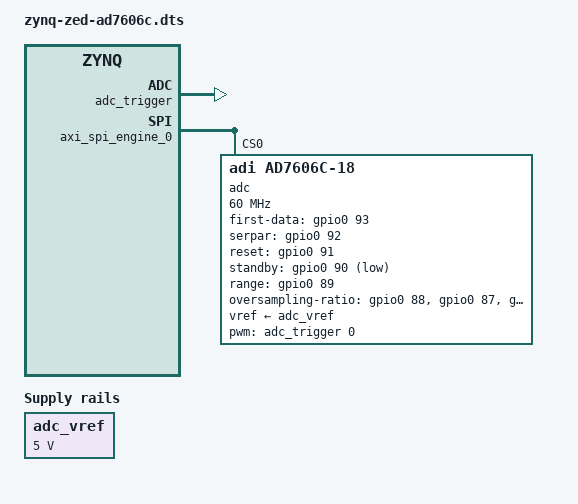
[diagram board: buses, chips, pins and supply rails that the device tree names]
// SPDX-License-Identifier: GPL-2.0
/*
 * Analog Devices AD7606C
 * https://www.analog.com/en/products/ad7606c-18.html
 * https://wiki.analog.com/resources/tools-software/linux-drivers/platforms/zynq
 *
 * hdl_project: <ad760x_fmc/zed>
 * board_revision: <>
 *
 * Copyright (C) 2012-2019 Analog Devices Inc.
 */
/dts-v1/;

#include <dt-bindings/gpio/gpio.h>
#include <dt-bindings/interrupt-controller/irq.h>
#include "zynq-zed.dtsi"
#include "zynq-zed-adv7511.dtsi"

/ {
	adc_vref: regulator-vref {
		compatible = "regulator-fixed";
		regulator-name = "fixed-supply";
		regulator-min-microvolt = <5000000>;
		regulator-max-microvolt = <5000000>;
		regulator-always-on;
	};
};

&fpga_axi {
	rx_dma: rx-dmac@44a30000 {
		compatible = "adi,axi-dmac-1.00.a";
		reg = <0x44a30000 0x1000>;
		#dma-cells = <1>;
		interrupt-parent = <&intc>;
		interrupts = <0 57 IRQ_TYPE_LEVEL_HIGH>;
		clocks = <&clkc 16>;

		adi,channels {
			#size-cells = <0>;
			#address-cells = <1>;

			dma-channel@0 {
				reg = <0>;
				adi,source-bus-width = <256>;
				adi,source-bus-type = <1>;
				adi,destination-bus-width = <64>;
				adi,destination-bus-type = <0>;
			};
		};
	};

	adc_trigger: pwm@0x44b00000 {
		compatible = "adi,axi-pwmgen";
		reg = <0x44b00000 0x1000>;
		label = "ad7606_pwm_gen";
		#pwm-cells = <2>;
		clocks = <&spi_clk>;
	};

	spi_clk: axi-clkgen@0x44a70000 {
		compatible = "adi,axi-clkgen-2.00.a";
		reg = <0x44a70000 0x10000>;
		#clock-cells = <0>;
		clocks = <&clkc 15>, <&clkc 15>;
		clock-names = "s_axi_aclk", "clkin1";
		clock-output-names = "spi_clk";
	};

	axi_spi_engine_0: spi@44a00000 {
		compatible = "adi,axi-spi-engine-1.00.a";
		reg = <0x44a00000 0x1000>;
		interrupt-parent = <&intc>;
		interrupts = <0 56 IRQ_TYPE_LEVEL_HIGH>;
		clock-names = "s_axi_aclk", "spi_clk";
		clocks = <&clkc 15 &spi_clk>;
		num-cs = <1>;

		#address-cells = <0x1>;
		#size-cells = <0x0>;

		adc@0 {
			#address-cells = <1>;
			#size-cells = <0>;
			compatible = "adi,ad7606c-18";
			reg = <0>;

			spi-max-frequency = <60000000>;
			spi-cpha;

			clocks = <&spi_clk>;
			clock-names = "ref_clk";
			
			dmas = <&rx_dma 0>;
			dma-names = "rx";
			
			pwms = <&adc_trigger 0 0>;
			pwm-names = "cnv_gen";
			
			vref-supply = <&adc_vref>;
			
			adi,first-data-gpios = <&gpio0 93 GPIO_ACTIVE_HIGH>;
			adi,serpar-gpios = <&gpio0 92 GPIO_ACTIVE_HIGH>;
			adi,reset-gpios = <&gpio0 91 GPIO_ACTIVE_HIGH>;
			adi,standby-gpios = <&gpio0 90 GPIO_ACTIVE_LOW>;
			adi,range-gpios = <&gpio0 89 GPIO_ACTIVE_HIGH>;
			adi,oversampling-ratio-gpios = <&gpio0 88 GPIO_ACTIVE_HIGH
											&gpio0 87 GPIO_ACTIVE_HIGH
											&gpio0 86 GPIO_ACTIVE_HIGH>;
		};
	};
};
